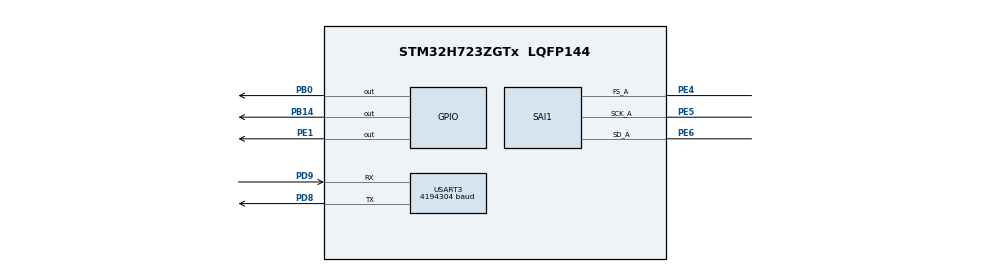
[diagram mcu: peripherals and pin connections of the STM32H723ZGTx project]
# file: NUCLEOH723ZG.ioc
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CORTEX_M7.CPU_DCache=Enabled
CORTEX_M7.CPU_ICache=Enabled
CORTEX_M7.Enable-Cortex_Memory_Protection_Unit_Region0_Settings=__NULL
CORTEX_M7.Enable-Cortex_Memory_Protection_Unit_Region1_Settings=__NULL
CORTEX_M7.MPU_Control=MPU_HFNMI_PRIVDEF
Dma.Request0=SAI1_A
Dma.Request1=USART3_TX
Dma.SAI1_A.0.Direction=DMA_PERIPH_TO_MEMORY
Dma.SAI1_A.0.EventEnable=DISABLE
Dma.SAI1_A.0.FIFOMode=DMA_FIFOMODE_ENABLE
Dma.SAI1_A.0.FIFOThreshold=DMA_FIFO_THRESHOLD_FULL
Dma.SAI1_A.0.Instance=DMA1_Stream0
Dma.SAI1_A.0.MemBurst=DMA_MBURST_INC4
Dma.SAI1_A.0.MemDataAlignment=DMA_MDATAALIGN_HALFWORD
Dma.SAI1_A.0.MemInc=DMA_MINC_ENABLE
Dma.SAI1_A.0.Mode=DMA_CIRCULAR
Dma.SAI1_A.0.PeriphBurst=DMA_PBURST_SINGLE
Dma.SAI1_A.0.PeriphDataAlignment=DMA_PDATAALIGN_HALFWORD
Dma.SAI1_A.0.PeriphInc=DMA_PINC_DISABLE
Dma.SAI1_A.0.Polarity=HAL_DMAMUX_REQ_GEN_RISING
Dma.SAI1_A.0.Priority=DMA_PRIORITY_VERY_HIGH
Dma.SAI1_A.0.RequestNumber=1
Dma.SAI1_A.0.SignalID=NONE
Dma.SAI1_A.0.SyncEnable=DISABLE
Dma.SAI1_A.0.SyncPolarity=HAL_DMAMUX_SYNC_NO_EVENT
Dma.SAI1_A.0.SyncRequestNumber=1
Dma.SAI1_A.0.SyncSignalID=NONE
Dma.USART3_TX.1.Direction=DMA_MEMORY_TO_PERIPH
Dma.USART3_TX.1.EventEnable=DISABLE
Dma.USART3_TX.1.FIFOMode=DMA_FIFOMODE_DISABLE
Dma.USART3_TX.1.Instance=DMA1_Stream1
Dma.USART3_TX.1.MemDataAlignment=DMA_MDATAALIGN_BYTE
Dma.USART3_TX.1.MemInc=DMA_MINC_ENABLE
Dma.USART3_TX.1.Mode=DMA_NORMAL
Dma.USART3_TX.1.PeriphDataAlignment=DMA_PDATAALIGN_BYTE
Dma.USART3_TX.1.PeriphInc=DMA_PINC_DISABLE
Dma.USART3_TX.1.Polarity=HAL_DMAMUX_REQ_GEN_RISING
Dma.USART3_TX.1.Priority=DMA_PRIORITY_VERY_HIGH
Dma.USART3_TX.1.RequestNumber=1
Dma.USART3_TX.1.SignalID=NONE
Dma.USART3_TX.1.SyncEnable=DISABLE
Dma.USART3_TX.1.SyncPolarity=HAL_DMAMUX_SYNC_NO_EVENT
Dma.USART3_TX.1.SyncRequestNumber=1
Dma.USART3_TX.1.SyncSignalID=NONE
Mcu.Family=STM32H7
Mcu.Name=STM32H723ZGTx
Mcu.Package=LQFP144
NVIC.DMA1_Stream0_IRQn=true\:0\:0\:false\:false\:true\:false\:true\:true
NVIC.DMA1_Stream1_IRQn=true\:0\:0\:false\:false\:true\:false\:true\:true
NVIC.PriorityGroup=NVIC_PRIORITYGROUP_4
NVIC.SAI1_IRQn=true\:0\:0\:false\:false\:true\:true\:true\:true
NVIC.USART3_IRQn=true\:0\:0\:false\:false\:true\:true\:true\:true
PB0.Signal=GPIO_Output
PB14.Signal=GPIO_Output
PD8.Mode=Asynchronous
PD8.Signal=USART3_TX
PD9.Mode=Asynchronous
PD9.Signal=USART3_RX
PE1.Signal=GPIO_Output
PE4.Mode=SAI_A_Master
PE4.Signal=SAI1_FS_A
PE5.Mode=SAI_A_Master
PE5.Signal=SAI1_SCK_A
PE6.Mode=SAI_A_Master
PE6.Signal=SAI1_SD_A
PH0-OSC_IN.Mode=HSE-External-Clock-Source
PH0-OSC_IN.Signal=RCC_OSC_IN
ProjectManager.HeapSize=0x200
ProjectManager.StackSize=0x400
ProjectManager.TargetToolchain=CMake
RCC.ADCFreq_Value=500000
RCC.APB1Freq_Value=137500000
RCC.APB2Freq_Value=137500000
RCC.APB3Freq_Value=137500000
RCC.APB4Freq_Value=137500000
RCC.CortexFreq_Value=550000000
RCC.D1PPRE=RCC_APB3_DIV2
RCC.D2PPRE1=RCC_APB1_DIV2
RCC.D2PPRE2=RCC_APB2_DIV2
RCC.D3PPRE=RCC_APB4_DIV2
RCC.DIVM1=4
RCC.DIVM3=4
RCC.DIVN1=275
RCC.DIVN2=4
RCC.DIVN3=196
RCC.DIVP1=1
RCC.DIVP3=8
RCC.DIVQ1=4
RCC.HCLKFreq_Value=275000000
RCC.HPRE=RCC_HCLK_DIV2
RCC.HSE_VALUE=8000000
RCC.PLL2FRACN=0
RCC.PLL3FRACN=4981
RCC.PLLFRACN=0
RCC.PLLSourceVirtual=RCC_PLLSOURCE_HSE
RCC.SAI1CLockSelection=RCC_SAI1CLKSOURCE_PLL3
RCC.SYSCLKFreq_VALUE=550000000
RCC.SYSCLKSource=RCC_SYSCLKSOURCE_PLLCLK
RCC.USBFreq_Value=137500000
SAI1.ActiveFrameLength-SAI_A_Master=1
SAI1.AudioFrequency-SAI_A_Master=SAI_AUDIO_FREQUENCY_16K
SAI1.AudioMode-SAI_A_Master=SAI_MODEMASTER_RX
SAI1.ClockStrobing-SAI_A_Master=SAI_CLOCKSTROBING_RISINGEDGE
SAI1.DataSize-SAI_A_Master=SAI_DATASIZE_16
SAI1.ErrorAudioFreq-SAI_A_Master=0.0 %
SAI1.FIFOThreshold-SAI_A_Master=SAI_FIFOTHRESHOLD_HF
SAI1.FSOffset-SAI_A_Master=SAI_FS_BEFOREFIRSTBIT
SAI1.FSPolarity-SAI_A_Master=SAI_FS_ACTIVE_HIGH
SAI1.FrameLength-SAI_A_Master=64
SAI1.Instance-SAI_A_Master=SAI$Index_Block_A
SAI1.MckOutput-SAI_A_Master=SAI_MCK_OUTPUT_DISABLE
SAI1.RealAudioFreq-SAI_A_Master=16.0 KHz
SAI1.SlotActive-SAI_A_Master=0x00000001
SAI1.SlotNumber-SAI_A_Master=2
SAI1.SlotSize-SAI_A_Master=SAI_SLOTSIZE_32B
SAI1.VirtualMode-SAI_A_Master=VM_MASTER
SAI1.VirtualSlotActive-SAI_A_Master=SAI_SLOT_USERSETTING
SAI1.VirtualSlotActive0-SAI_A_Master=true
SAI1.VirtualSlotActive1-SAI_A_Master=false
USART3.BaudRate=4194304
USART3.VirtualMode-Asynchronous=VM_ASYNC
VP_MEMORYMAP_VS_MEMORYMAP.Mode=CurAppReg
board=NUCLEO-H723ZG

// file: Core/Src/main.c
/* USER CODE BEGIN Header */
/**
  ******************************************************************************
  * @file           : main.c
  * @brief          : Main program body
  ******************************************************************************
  * @attention
  *
  * Copyright (c) 2026 STMicroelectronics.
  * All rights reserved.
  *
  * This software is licensed under terms that can be found in the LICENSE file
  * in the root directory of this software component.
  * If no LICENSE file comes with this software, it is provided AS-IS.
  *
  ******************************************************************************
  */
/* USER CODE END Header */
#include "main.h"
#include "dma.h"
#include "sai.h"
#include "usart.h"
#include "gpio.h"

/* USER CODE BEGIN Includes */
#include "app_entry.h"
/* USER CODE END Includes */

void SystemClock_Config(void);
static void MPU_Config(void);

int main(void)
{

  /* MPU Configuration--------------------------------------------------------*/
  MPU_Config();

  /* Enable the CPU Cache */

  /* Enable I-Cache---------------------------------------------------------*/
  SCB_EnableICache();

  /* Enable D-Cache---------------------------------------------------------*/
  SCB_EnableDCache();

  /* MCU Configuration--------------------------------------------------------*/

  /* Reset of all peripherals, Initializes the Flash interface and the Systick. */
  HAL_Init();

  /* Configure the system clock */
  SystemClock_Config();

  /* Initialize all configured peripherals */
  MX_GPIO_Init();
  MX_DMA_Init();
  MX_SAI1_Init();
  MX_USART3_UART_Init();
  /* USER CODE BEGIN 2 */
  app_main();
  /* USER CODE END 2 */

  /* Infinite loop */
  while (1)
  {

    /* USER CODE BEGIN 3 */

	  // char input[6];
	  // HAL_UART_Receive(&huart3, (uint8_t*)&input, 5, HAL_MAX_DELAY);
	  // input[5] = '\0';
	  // printf("%s\r\n",input);
	  // HAL_Delay(250);

  }
  /* USER CODE END 3 */
}

void SystemClock_Config(void)
{
  RCC_OscInitTypeDef RCC_OscInitStruct = {0};
  RCC_ClkInitTypeDef RCC_ClkInitStruct = {0};

  /** Supply configuration update enable
  */
  HAL_PWREx_ConfigSupply(PWR_LDO_SUPPLY);

  /** Configure the main internal regulator output voltage
  */
  __HAL_PWR_VOLTAGESCALING_CONFIG(PWR_REGULATOR_VOLTAGE_SCALE0);

  while(!__HAL_PWR_GET_FLAG(PWR_FLAG_VOSRDY)) {}

  /** Initializes the RCC Oscillators according to the specified parameters
  * in the RCC_OscInitTypeDef structure.
  */
  RCC_OscInitStruct.OscillatorType = RCC_OSCILLATORTYPE_HSE;
  RCC_OscInitStruct.HSEState = RCC_HSE_BYPASS;
  RCC_OscInitStruct.PLL.PLLState = RCC_PLL_ON;
  RCC_OscInitStruct.PLL.PLLSource = RCC_PLLSOURCE_HSE;
  RCC_OscInitStruct.PLL.PLLM = 4;
  RCC_OscInitStruct.PLL.PLLN = 275;
  RCC_OscInitStruct.PLL.PLLP = 1;
  RCC_OscInitStruct.PLL.PLLQ = 4;
  RCC_OscInitStruct.PLL.PLLR = 2;
  RCC_OscInitStruct.PLL.PLLRGE = RCC_PLL1VCIRANGE_1;
  RCC_OscInitStruct.PLL.PLLVCOSEL = RCC_PLL1VCOWIDE;
  RCC_OscInitStruct.PLL.PLLFRACN = 0;
  if (HAL_RCC_OscConfig(&RCC_OscInitStruct) != HAL_OK)
  {
    Error_Handler();
  }

  /** Initializes the CPU, AHB and APB buses clocks
  */
  RCC_ClkInitStruct.ClockType = RCC_CLOCKTYPE_HCLK|RCC_CLOCKTYPE_SYSCLK
                              |RCC_CLOCKTYPE_PCLK1|RCC_CLOCKTYPE_PCLK2
                              |RCC_CLOCKTYPE_D3PCLK1|RCC_CLOCKTYPE_D1PCLK1;
  RCC_ClkInitStruct.SYSCLKSource = RCC_SYSCLKSOURCE_PLLCLK;
  RCC_ClkInitStruct.SYSCLKDivider = RCC_SYSCLK_DIV1;
  RCC_ClkInitStruct.AHBCLKDivider = RCC_HCLK_DIV2;
  RCC_ClkInitStruct.APB3CLKDivider = RCC_APB3_DIV2;
  RCC_ClkInitStruct.APB1CLKDivider = RCC_APB1_DIV2;
  RCC_ClkInitStruct.APB2CLKDivider = RCC_APB2_DIV2;
  RCC_ClkInitStruct.APB4CLKDivider = RCC_APB4_DIV2;

  if (HAL_RCC_ClockConfig(&RCC_ClkInitStruct, FLASH_LATENCY_3) != HAL_OK)
  {
    Error_Handler();
  }
}

 /* MPU Configuration */

void MPU_Config(void)
{

  /* Disables the MPU */
  HAL_MPU_Disable();

  /* Enables the MPU */
  HAL_MPU_Enable(MPU_HFNMI_PRIVDEF);

}

void Error_Handler(void)
{
  __disable_irq();
  while (1)
  {
  }
}
